VERSION "MultiNode_DBC_Example"

NS_ :

BS_:

BU_: ECU_ENGINE ECU_BCM ECU_TCU ECU_CLUSTER ECU_ADAS

BO_ 100 ENGINE_STATUS: 8 ECU_ENGINE
 SG_ EngineSpeed : 0|16@1+ (0.125,0) [0|8000] "rpm" ECU_CLUSTER,ECU_ADAS
 SG_ EngineLoad  : 16|8@1+ (0.4,0) [0|100] "%" ECU_TCU

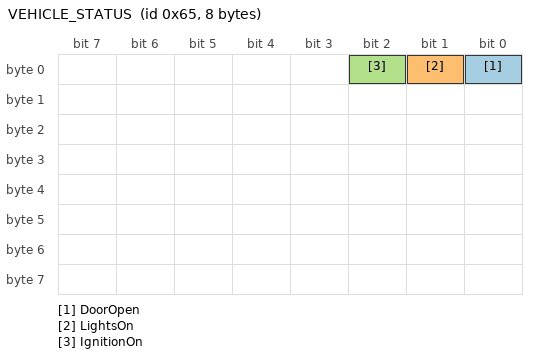
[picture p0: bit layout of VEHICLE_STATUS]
BO_ 101 VEHICLE_STATUS: 8 ECU_BCM
 SG_ DoorOpen    : 0|1@1+ (1,0) [0|1] "" ECU_CLUSTER
 SG_ LightsOn    : 1|1@1+ (1,0) [0|1] "" ECU_CLUSTER
 SG_ IgnitionOn  : 2|1@1+ (1,0) [0|1] "" ECU_ENGINE,ECU_TCU

BO_ 102 TRANSMISSION_STATUS: 8 ECU_TCU
 SG_ CurrentGear : 0|8@1+ (1,0) [0|10] "" ECU_CLUSTER
 SG_ TorqueReq   : 8|16@1+ (1,0) [0|500] "Nm" ECU_ENGINE

BO_ 103 ADAS_DATA: 8 ECU_ADAS
 SG_ CruiseActive : 0|1@1+ (1,0) [0|1] "" ECU_CLUSTER
 SG_ TargetSpeed  : 8|16@1+ (0.01,0) [0|250] "km/h" ECU_ENGINE

BO_ 104 DIAGNOSTIC: 8 ECU_BCM
 SG_ FaultCode : 0|16@1+ (1,0) [0|65535] "" ECU_CLUSTER
